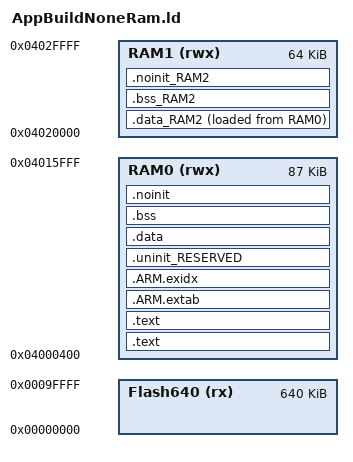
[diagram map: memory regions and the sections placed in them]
/*
 * GENERATED FILE - DO NOT EDIT
 * (c) Code Red Technologies Ltd, 2008-2013
 * (c) NXP Semiconductors 2013-2017
 * Generated linker script file for JN5189
 * Created from linkscript.ldt by FMCreateLinkLibraries
 * Using Freemarker v2.3.23
 * LPCXpresso v8.2.2 [Build 650] [2016-09-09]  on 05-Jan-2017 14:07:01
 */

MEMORY
{
  /* Define each memory region */
  Flash640 (rx) : ORIGIN = 0x0,       LENGTH = 0xa0000 /* 640K bytes (alias Flash) */  
  RAM0 (rwx)    : ORIGIN = 0x4000400, LENGTH = 0x15c00 /* 87K bytes (alias RAM) */  
  RAM1 (rwx)    : ORIGIN = 0x4020000, LENGTH = 0x10000 /* 64K bytes (alias RAM2) */  
}

  /* Define a symbol for the top of each memory region */
  __base_Flash640 = 0x0  ; /* Flash640 */  
  __base_Flash = 0x0 ; /* Flash */  
  __top_Flash640 = 0x0 + 0xa0000 ; /* 640K bytes */  
  __top_Flash = 0x0 + 0xa0000 ; /* 640K bytes */  
  __base_RAM0 = 0x4000400  ; /* RAM0 */  
  __base_RAM = 0x4000400 ; /* RAM */  
  __top_RAM0 = 0x4000400 + 0x15c00 ; /* 87K bytes */  
  __top_RAM = 0x4000400 + 0x15c00 ; /* 87K bytes */  
  __base_RAM1 = 0x4020000  ; /* RAM1 */  
  __base_RAM2 = 0x4020000 ; /* RAM2 */  
  __top_RAM1 = 0x4020000 + 0x10000 ; /* 64K bytes */  
  __top_RAM2 = 0x4020000 + 0x10000 ; /* 64K bytes */  
  HEAP_SIZE  = 0x6F4;
ENTRY(ResetISR)

SECTIONS
{
    /* MAIN TEXT SECTION */
    .text : ALIGN(4)
    {
        FILL(0xff)
        __vectors_start__ = ABSOLUTE(.) ;
        KEEP(*(.isr_vector))
        /* Global Section Table */
        . = ALIGN(4) ; 
        __section_table_start = .;
        __data_section_table = .;
        LONG(LOADADDR(.data));
        LONG(    ADDR(.data));
        LONG(  SIZEOF(.data));
        LONG(LOADADDR(.data_RAM2));
        LONG(    ADDR(.data_RAM2));
        LONG(  SIZEOF(.data_RAM2));
        __data_section_table_end = .;
        __bss_section_table = .;
        LONG(    ADDR(.bss));
        LONG(  SIZEOF(.bss));
        LONG(    ADDR(.bss_RAM2));
        LONG(  SIZEOF(.bss_RAM2));
        __bss_section_table_end = .;
        __section_table_end = . ;
	    /* End of Global Section Table */

        *(.after_vectors*)

    } >RAM0

    .text : ALIGN(4)    
    {
        *(.text*)
        *(.rodata .rodata.* .constdata .constdata.*)
        . = ALIGN(4);
    } > RAM0
    /*
     * for exception handling/unwind - some Newlib functions (in common
     * with C++ and STDC++) use this. 
     */
    .ARM.extab : ALIGN(4) 
    {
        *(.ARM.extab* .gnu.linkonce.armextab.*)
    } > RAM0
    __exidx_start = .;

    .ARM.exidx : ALIGN(4)
    {
        *(.ARM.exidx* .gnu.linkonce.armexidx.*)
    } > RAM0
    __exidx_end = .;

    _etext = .;
        
    /* DATA section for RAM1 */
    .data_RAM2 : ALIGN(4)
    {
        FILL(0xff)
        PROVIDE(__start_data_RAM2 = .) ;
        *(.ramfunc.$RAM2)
        *(.ramfunc.$RAM1)
        *(.data.$RAM2*)
        *(.data.$RAM1*)
        . = ALIGN(4) ;
        PROVIDE(__end_data_RAM2 = .) ;
     } > RAM1 AT>RAM0

    /* MAIN DATA SECTION */
    .uninit_RESERVED : ALIGN(4)
    {
        KEEP(*(.bss.$RESERVED*))
        . = ALIGN(4) ;
        _end_uninit_RESERVED = .;
    } > RAM0

    /* Main DATA section (RAM0) */
    .data : ALIGN(4)
    {
       FILL(0xff)
       _data = . ;
       *(vtable)
       *(.ramfunc*)
       *(.data*)
       . = ALIGN(4) ;
       _edata = . ;
    } > RAM0 AT>RAM0

    /* BSS section for RAM1 */
    .bss_RAM2 (NOLOAD) : ALIGN(4)
    {
       PROVIDE(__start_bss_RAM2 = .) ;

       /* MAC buffer section: must be within a 32kB block */
       . = ALIGN(32768);
       __mac_buffer_base = .;
       *(.mac_buffer)

       *(.bss.$RAM2*)
       *(.bss.$RAM1*)
       . = ALIGN (. != 0 ? 4 : 1) ; /* avoid empty segment */
       PROVIDE(__end_bss_RAM2 = .) ;
    } > RAM1 

    /* MAIN BSS SECTION */
    .bss : ALIGN(4)
    {
        _bss = .;
        *(.bss*)
        *(COMMON)
        . = ALIGN(4) ;
        _ebss = .;

        PROVIDE(end = .);
    } > RAM0

    /* NOINIT section for RAM1 */
    .noinit_RAM2 (NOLOAD) : ALIGN(4)
    {
       *(.noinit.$RAM2*)
       *(.noinit.$RAM1*)
       . = ALIGN(4) ;
    } > RAM1 

    /* DEFAULT NOINIT SECTION */
    .noinit (NOLOAD): ALIGN(4)
    {
        _noinit = .;
        *(.noinit*) 
        . = ALIGN(4) ;
        _end_noinit = .;
        _end_fw_retention = .;
    } > RAM0

    PROVIDE(_pvHeapStart = DEFINED(__user_heap_base) ? __user_heap_base : .);
    PROVIDE(_pvHeapLimit = _pvHeapStart + (HEAP_SIZE));
    PROVIDE(_stack_low_water_mark = (__top_RAM0 -(__top_RAM0 - _pvHeapLimit)));
    PROVIDE(_vStackTop = DEFINED(__user_stack_top) ? __user_stack_top : __top_RAM0 - 0);
}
